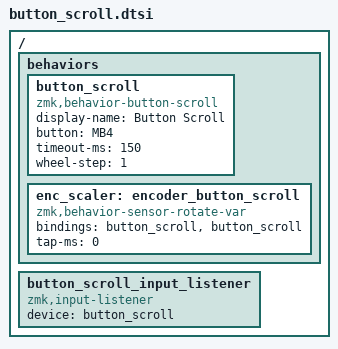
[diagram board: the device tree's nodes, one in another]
#include <dt-bindings/zmk/pointing.h>

/ {
    behaviors {
        /omit-if-no-ref/ button_scroll: button_scroll {
            compatible = "zmk,behavior-button-scroll";
            #binding-cells = <1>;
            display-name = "Button Scroll";
            button = <MB4>;
            timeout-ms = <150>;
            wheel-step = <1>;
        };

        /omit-if-no-ref/ enc_scaler: encoder_button_scroll {
            compatible = "zmk,behavior-sensor-rotate-var";
            #sensor-binding-cells = <2>;
            bindings = <&button_scroll>, <&button_scroll>;
            tap-ms = <0>;
        };
    };

    button_scroll_input_listener {
        compatible = "zmk,input-listener";
        device = <&button_scroll>;
    };
};
